[part 1 of 4: package /DBC_SysDesc/Pkg_Cluster]
AUTOSAR XML (schema 4-2-2)
package /DBC_SysDesc/Pkg_Cluster
  6 x j 1939 cluster, all with protocol-name=J1939:
    Can_Network_ACAN
      can physical channel Can_Network_ACAN_Channel: comm-connectors=Conn_Can_Network_ACAN_CGW
        frame EEC3DI_DCU_ACAN_IN: id 0x18FEDF3D, to CGW, frame-length=8, can-addressing-mode=EXTENDED, can-frame-rx-behavior=ANY
          pdu EEC3DI_DCU_ACAN_IN: length=8, transmission-mode-condition{data-filter={data-filter-type=ALWAYS, max=3, min=0, offset=0}, i-signal-in-i-pdu=NOx_Dew_Point_Start_Doosan_EEC3DI_DCU_ACAN}, transmission-mode-false-timing=event-controlled-timing=number-of-repetitions=0, transmission-mode-true-timing=event-controlled-timing=number-of-repetitions=0
            signal NOx_Dew_Point_Start_Doosan_EEC3DI_DCU_ACAN: start 58, 2 bit, little-endian, init-value=0, base-type=uint8, compu-method=CompuMethod_NOx_Dew_Point_Start_Doosan_EEC3DI_DCU, to CGW
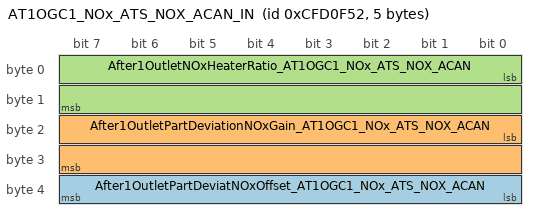
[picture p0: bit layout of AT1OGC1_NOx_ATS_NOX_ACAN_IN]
        frame AT1OGC1_NOx_ATS_NOX_ACAN_IN: id 0xCFD0F52, to CGW, frame-length=5, can-addressing-mode=EXTENDED, can-frame-rx-behavior=ANY
          pdu AT1OGC1_NOx_ATS_NOX_ACAN_IN: length=5, transmission-mode-false-timing=event-controlled-timing=number-of-repetitions=0, transmission-mode-true-timing=event-controlled-timing=number-of-repetitions=0
            transmission-mode-conditions:
              {data-filter={data-filter-type=ALWAYS, max=250, min=0}, i-signal-in-i-pdu=After1OutletPartDeviatNOxOffset_AT1OGC1_NOx_ATS_NOX_ACAN}
              {data-filter={data-filter-type=NEW-IS-WITHIN, max=2000, min=0}, i-signal-in-i-pdu=After1OutletPartDeviationNOxGain_AT1OGC1_NOx_ATS_NOX_ACAN}
              {data-filter={data-filter-type=NEW-IS-WITHIN, max=64255, min=0, offset=0}, i-signal-in-i-pdu=After1OutletNOxHeaterRatio_AT1OGC1_NOx_ATS_NOX_ACAN}
            signal After1OutletPartDeviatNOxOffset_AT1OGC1_NOx_ATS_NOX_ACAN: start 32, 8 bit, little-endian, init-value=0, base-type=uint8, compu {raw=phys+125 for phys -125..125; unit ppm}, to CGW  # New part deviation NOx_Offset to correct(recalculate) sensor signal on th Engine ECU sideNew part deviation NOx_Offset to correct(recalculate) sensor signal on th Engine ECU side"
            signal After1OutletPartDeviationNOxGain_AT1OGC1_NOx_ATS_NOX_ACAN: start 16, 16 bit, little-endian, init-value=0, base-type=uint16, compu {raw=phys*10+1000 for phys -100..100; unit pct}, to CGW  # New Part deviation NOx_Gain to correct(recalculate) sensor signal on the Engine ECU sideNew Part deviation NOx_Gain to correct(recalculate) sensor signal on the Engine ECU side"
            signal After1OutletNOxHeaterRatio_AT1OGC1_NOx_ATS_NOX_ACAN: start 0, 16 bit, little-endian, init-value=0, base-type=uint16, compu {raw=phys*1000 for phys 0..64.255}, to CGW  # Heater ratio to determine temperature at sensor tip.Heater ratio to determine temperature at sensor tip."
    Can_Network_CCAN
      can physical channel Can_Network_CCAN_Channel: comm-connectors=Conn_Can_Network_CCAN_CGW
        frame TPM_TPMS_CCAN_IN: id 0x18FFC833, to CGW, frame-length=8, can-addressing-mode=EXTENDED, can-frame-rx-behavior=ANY
          pdu TPM_TPMS_CCAN_IN: length=8, transmission-mode-false-timing=event-controlled-timing=number-of-repetitions=0, transmission-mode-true-timing=event-controlled-timing=number-of-repetitions=0
        frame DM1_TPMS_CCAN_IN: id 0x18FECA33, to CGW, frame-length=22, can-addressing-mode=EXTENDED, can-frame-rx-behavior=ANY
          pdu DM1_TPMS_CCAN_IN: length=22, transmission-mode-false-timing=event-controlled-timing=number-of-repetitions=0, transmission-mode-true-timing=event-controlled-timing=number-of-repetitions=0
        frame AC2TB_ACU_CCAN_IN: id 0x18FF4A53, to CGW, frame-length=8, can-addressing-mode=EXTENDED, can-frame-rx-behavior=ANY
          pdu AC2TB_ACU_CCAN_IN: length=8, transmission-mode-false-timing=event-controlled-timing=number-of-repetitions=0, transmission-mode-true-timing=event-controlled-timing=number-of-repetitions=0
        frame DM1_ACU_CCAN_IN: id 0x18FECA53, to CGW, frame-length=22, can-addressing-mode=EXTENDED, can-frame-rx-behavior=ANY
          pdu DM1_ACU_CCAN_IN: length=22, transmission-mode-false-timing=event-controlled-timing=number-of-repetitions=0, transmission-mode-true-timing=event-controlled-timing=number-of-repetitions=0
        frame TCO1_Tachograph_DTG_CAN_CLOCK_CCAN_IN: id 0xCFE6CEE, to CGW, frame-length=8, can-addressing-mode=EXTENDED, can-frame-rx-behavior=ANY
          pdu TCO1_Tachograph_DTG_CAN_CLOCK_CCAN_IN: length=8, transmission-mode-false-timing=event-controlled-timing=number-of-repetitions=0, transmission-mode-true-timing=event-controlled-timing=number-of-repetitions=0
        frame TD_DTG_CAN_CLOCK_CCAN_IN: id 0x18FEE6EE, to CGW, frame-length=8, can-addressing-mode=EXTENDED, can-frame-rx-behavior=ANY
          pdu TD_DTG_CAN_CLOCK_CCAN_IN: length=8, transmission-mode-false-timing=event-controlled-timing=number-of-repetitions=0, transmission-mode-true-timing=event-controlled-timing=number-of-repetitions=0
        frame TB2SM_T_BOX_T_LINK_CCAN_IN: id 0x18EF1F4A, to CGW, frame-length=8, can-addressing-mode=EXTENDED, can-frame-rx-behavior=ANY
          pdu TB2SM_T_BOX_T_LINK_CCAN_IN: length=8, transmission-mode-false-timing=event-controlled-timing=number-of-repetitions=0, transmission-mode-true-timing=event-controlled-timing=number-of-repetitions=0
        frame BDS_ACU_CCAN_IN: id 0x18FD1753, to CGW, frame-length=8, can-addressing-mode=EXTENDED, can-frame-rx-behavior=ANY
          pdu BDS_ACU_CCAN_IN: length=8, transmission-mode-false-timing=event-controlled-timing=number-of-repetitions=0, transmission-mode-true-timing=event-controlled-timing=number-of-repetitions=0
        frame AC2IC_ACU_CCAN_IN: id 0x18FF1753, to CGW, frame-length=8, can-addressing-mode=EXTENDED, can-frame-rx-behavior=ANY
          pdu AC2IC_ACU_CCAN_IN: length=8, transmission-mode-false-timing=event-controlled-timing=number-of-repetitions=0, transmission-mode-true-timing=event-controlled-timing=number-of-repetitions=0
        frame CACI5_HVAC_CCAN_IN: id 0x18FC1C19, to CGW, frame-length=8, can-addressing-mode=EXTENDED, can-frame-rx-behavior=ANY
          pdu CACI5_HVAC_CCAN_IN: length=8, transmission-mode-false-timing=event-controlled-timing=number-of-repetitions=0, transmission-mode-true-timing=event-controlled-timing=number-of-repetitions=0
        frame CACI6_HVAC_CCAN_IN: id 0x18FB1C19, to CGW, frame-length=8, can-addressing-mode=EXTENDED, can-frame-rx-behavior=ANY
          pdu CACI6_HVAC_CCAN_IN: length=8, transmission-mode-false-timing=event-controlled-timing=number-of-repetitions=0, transmission-mode-true-timing=event-controlled-timing=number-of-repetitions=0
        frame VDHR_Tachograph_DTG_CAN_CLOCK_CCAN_IN: id 0x18FEC1EE, to CGW, frame-length=8, can-addressing-mode=EXTENDED, can-frame-rx-behavior=ANY
          pdu VDHR_Tachograph_DTG_CAN_CLOCK_CCAN_IN: length=8, transmission-mode-false-timing=event-controlled-timing=number-of-repetitions=0, transmission-mode-true-timing=event-controlled-timing=number-of-repetitions=0
        frame ETC7_TCU_CCAN_OUT: id 0x18FE4A03, from CGW, frame-length=8, can-addressing-mode=EXTENDED
          pdu ETC7_TCU_CCAN_OUT: length=8, transmission-mode-false-timing=event-controlled-timing=number-of-repetitions=0, transmission-mode-true-timing=event-controlled-timing=number-of-repetitions=0
        frame TCO1_IC_CCAN_OUT: id 0xCFE6C17, from CGW, frame-length=8, can-addressing-mode=EXTENDED
          pdu TCO1_IC_CCAN_OUT: length=8, transmission-mode-false-timing=event-controlled-timing=number-of-repetitions=0, transmission-mode-true-timing=event-controlled-timing=number-of-repetitions=0
        frame EEC1_ECU_CCAN_OUT: id 0xCF00400, from CGW, frame-length=8, can-addressing-mode=EXTENDED
          pdu EEC1_ECU_CCAN_OUT: length=8, transmission-mode-false-timing=event-controlled-timing=number-of-repetitions=0, transmission-mode-true-timing=event-controlled-timing=number-of-repetitions=0
        frame SWRC2AVN_SWRC_CCAN_OUT: id 0x18FF1C66, from CGW, frame-length=8, can-addressing-mode=EXTENDED
          pdu SWRC2AVN_SWRC_CCAN_OUT: length=8, transmission-mode-false-timing=event-controlled-timing=number-of-repetitions=0, transmission-mode-true-timing=event-controlled-timing=number-of-repetitions=0
        frame TxCCVS_ECU_CCAN_OUT: id 0x18FEF100, from CGW, frame-length=8, can-addressing-mode=EXTENDED
          pdu TxCCVS_ECU_CCAN_OUT: length=8, transmission-mode-false-timing=event-controlled-timing=number-of-repetitions=0, transmission-mode-true-timing=event-controlled-timing=number-of-repetitions=0
        frame ETC2_TCU_CCAN_OUT: id 0x18F00503, from CGW, frame-length=8, can-addressing-mode=EXTENDED
          pdu ETC2_TCU_CCAN_OUT: length=8, transmission-mode-false-timing=event-controlled-timing=number-of-repetitions=0, transmission-mode-true-timing=event-controlled-timing=number-of-repetitions=0
        frame EBC2_ABS_EBS_CCAN_OUT: id 0x18FEBF0B, from CGW, frame-length=8, can-addressing-mode=EXTENDED
          pdu EBC2_ABS_EBS_CCAN_OUT: length=8, transmission-mode-false-timing=event-controlled-timing=number-of-repetitions=0, transmission-mode-true-timing=event-controlled-timing=number-of-repetitions=0
        frame VDHR_IC_CCAN_OUT: id 0x18FEC117, from CGW, frame-length=8, can-addressing-mode=EXTENDED
          pdu VDHR_IC_CCAN_OUT: length=8, transmission-mode-false-timing=event-controlled-timing=number-of-repetitions=0, transmission-mode-true-timing=event-controlled-timing=number-of-repetitions=0
        frame IC2BC_IC_CCAN_OUT: id 0x18FF2117, from CGW, frame-length=8, can-addressing-mode=EXTENDED
          pdu IC2BC_IC_CCAN_OUT: length=8, transmission-mode-false-timing=event-controlled-timing=number-of-repetitions=0, transmission-mode-true-timing=event-controlled-timing=number-of-repetitions=0
        frame SM2BC_SMK_CCAN_OUT: id 0x18FF211F, from CGW, frame-length=8, can-addressing-mode=EXTENDED
          pdu SM2BC_SMK_CCAN_OUT: length=8, transmission-mode-false-timing=event-controlled-timing=number-of-repetitions=0, transmission-mode-true-timing=event-controlled-timing=number-of-repetitions=0
        frame CCVS1_BCM_CMD_CCAN_OUT: id 0x18FEF121, from CGW, frame-length=8, can-addressing-mode=EXTENDED
          pdu CCVS1_BCM_CMD_CCAN_OUT: length=8, transmission-mode-false-timing=event-controlled-timing=number-of-repetitions=0, transmission-mode-true-timing=event-controlled-timing=number-of-repetitions=0
        frame OEL_IC_CCAN_OUT: id 0xCFDCC27, from CGW, frame-length=8, can-addressing-mode=EXTENDED
          pdu OEL_IC_CCAN_OUT: length=8, transmission-mode-false-timing=event-controlled-timing=number-of-repetitions=0, transmission-mode-true-timing=event-controlled-timing=number-of-repetitions=0
        frame BC2CC_BCM_CMD_CCAN_OUT: id 0x18FF4721, from CGW, frame-length=8, can-addressing-mode=EXTENDED
          pdu BC2CC_BCM_CMD_CCAN_OUT: length=8, transmission-mode-false-timing=event-controlled-timing=number-of-repetitions=0, transmission-mode-true-timing=event-controlled-timing=number-of-repetitions=0
    Can_Network_ECAN
      can physical channel Can_Network_ECAN_Channel: comm-connectors=Conn_Can_Network_ECAN_CGW
        frame DM1_EHPS_ECAN_IN: id 0x18FECA13, to CGW, frame-length=22, can-addressing-mode=EXTENDED, can-frame-rx-behavior=ANY
          pdu DM1_EHPS_ECAN_IN: length=22, transmission-mode-false-timing=event-controlled-timing=number-of-repetitions=0, transmission-mode-true-timing=event-controlled-timing=number-of-repetitions=0
        frame EPSO2_EHPS_ECAN_IN: id 0x18FF0613, to CGW, frame-length=8, can-addressing-mode=EXTENDED, can-frame-rx-behavior=ANY
          pdu EPSO2_EHPS_ECAN_IN: length=8, transmission-mode-false-timing=event-controlled-timing=number-of-repetitions=0, transmission-mode-true-timing=event-controlled-timing=number-of-repetitions=0
        frame CM3_AWD_ECAN_IN: id 0x18FDD465, to CGW, frame-length=8, can-addressing-mode=EXTENDED, can-frame-rx-behavior=ANY
          pdu CM3_AWD_ECAN_IN: length=8, transmission-mode-false-timing=event-controlled-timing=number-of-repetitions=0, transmission-mode-true-timing=event-controlled-timing=number-of-repetitions=0
        frame SAS1_EHPS_ECAN_IN: id 0x18F01D13, to CGW, frame-length=8, can-addressing-mode=EXTENDED, can-frame-rx-behavior=ANY
          pdu SAS1_EHPS_ECAN_IN: length=8, transmission-mode-false-timing=event-controlled-timing=number-of-repetitions=0, transmission-mode-true-timing=event-controlled-timing=number-of-repetitions=0
        frame SAS2_EHPS_ECAN_IN: id 0x18F01D14, to CGW, frame-length=8, can-addressing-mode=EXTENDED, can-frame-rx-behavior=ANY
          pdu SAS2_EHPS_ECAN_IN: length=8, transmission-mode-false-timing=event-controlled-timing=number-of-repetitions=0, transmission-mode-true-timing=event-controlled-timing=number-of-repetitions=0
        frame EPSO1_EHPS_ECAN_IN: id 0x18FF0513, to CGW, frame-length=8, can-addressing-mode=EXTENDED, can-frame-rx-behavior=ANY
          pdu EPSO1_EHPS_ECAN_IN: length=8, transmission-mode-false-timing=event-controlled-timing=number-of-repetitions=0, transmission-mode-true-timing=event-controlled-timing=number-of-repetitions=0
        frame ESS2IC_ESS_ECAN_IN: id 0x18FF174D, to CGW, frame-length=8, can-addressing-mode=EXTENDED, can-frame-rx-behavior=ANY
          pdu ESS2IC_ESS_ECAN_IN: length=8, transmission-mode-false-timing=event-controlled-timing=number-of-repetitions=0, transmission-mode-true-timing=event-controlled-timing=number-of-repetitions=0
        frame TCI_AWD_ECAN_IN: id 0x18FD8365, to CGW, frame-length=8, can-addressing-mode=EXTENDED, can-frame-rx-behavior=ANY
          pdu TCI_AWD_ECAN_IN: length=8, transmission-mode-false-timing=event-controlled-timing=number-of-repetitions=0, transmission-mode-true-timing=event-controlled-timing=number-of-repetitions=0
        frame EEC1_ECU_ECAN_OUT: id 0xCF00400, from CGW, frame-length=8, can-addressing-mode=EXTENDED
          pdu EEC1_ECU_ECAN_OUT: length=8, transmission-mode-false-timing=event-controlled-timing=number-of-repetitions=0, transmission-mode-true-timing=event-controlled-timing=number-of-repetitions=0
        frame TCO1_Tachograph_DTG_CAN_CLOCK_ECAN_OUT: id 0xCFE6CEE, from CGW, frame-length=8, can-addressing-mode=EXTENDED
          pdu TCO1_Tachograph_DTG_CAN_CLOCK_ECAN_OUT: length=8, transmission-mode-false-timing=event-controlled-timing=number-of-repetitions=0, transmission-mode-true-timing=event-controlled-timing=number-of-repetitions=0
        frame ETC2_TCU_ECAN_OUT: id 0x18F00503, from CGW, frame-length=8, can-addressing-mode=EXTENDED
          pdu ETC2_TCU_ECAN_OUT: length=8, transmission-mode-false-timing=event-controlled-timing=number-of-repetitions=0, transmission-mode-true-timing=event-controlled-timing=number-of-repetitions=0
    Can_Network_LCAN
      can physical channel Can_Network_LCAN_Channel: comm-connectors=Conn_Can_Network_LCAN_CGW
        frame EBC5_CCM_LCAN_IN: id 0x18FDC40B, to CGW, frame-length=4, can-addressing-mode=EXTENDED, can-frame-rx-behavior=ANY
          pdu EBC5_CCM_LCAN_IN: length=4, transmission-mode-false-timing=event-controlled-timing=number-of-repetitions=0, transmission-mode-true-timing=event-controlled-timing=number-of-repetitions=0
        frame SMK1__SM2TB__SMK_LCAN_IN: id 0x18EF4A1F, to CGW, frame-length=8, can-addressing-mode=EXTENDED, can-frame-rx-behavior=ANY
          pdu SMK1__SM2TB__SMK_LCAN_IN: length=8, transmission-mode-false-timing=event-controlled-timing=number-of-repetitions=0, transmission-mode-true-timing=event-controlled-timing=number-of-repetitions=0
        frame LWSV_CCM_LCAN_IN: id 0x18FF170B, to CGW, frame-length=8, can-addressing-mode=EXTENDED, can-frame-rx-behavior=ANY
          pdu LWSV_CCM_LCAN_IN: length=8, transmission-mode-false-timing=event-controlled-timing=number-of-repetitions=0, transmission-mode-true-timing=event-controlled-timing=number-of-repetitions=0
        frame EBC1_CCM_LCAN_IN: id 0x18F00131, to CGW, frame-length=8, can-addressing-mode=EXTENDED, can-frame-rx-behavior=ANY
          pdu EBC1_CCM_LCAN_IN: length=8, transmission-mode-false-timing=event-controlled-timing=number-of-repetitions=0, transmission-mode-true-timing=event-controlled-timing=number-of-repetitions=0
        frame CC2BC_CCM_LCAN_IN: id 0x18FF2147, to CGW, frame-length=2, can-addressing-mode=EXTENDED, can-frame-rx-behavior=ANY
          pdu CC2BC_CCM_LCAN_IN: length=2, transmission-mode-false-timing=event-controlled-timing=number-of-repetitions=0, transmission-mode-true-timing=event-controlled-timing=number-of-repetitions=0
        frame CC2IC_CCM_LCAN_IN: id 0x18FF1747, to CGW, frame-length=8, can-addressing-mode=EXTENDED, can-frame-rx-behavior=ANY
          pdu CC2IC_CCM_LCAN_IN: length=8, transmission-mode-false-timing=event-controlled-timing=number-of-repetitions=0, transmission-mode-true-timing=event-controlled-timing=number-of-repetitions=0
        frame EBC4_CCM_LCAN_IN: id 0x1CFEAC0B, to CGW, frame-length=8, can-addressing-mode=EXTENDED, can-frame-rx-behavior=ANY
          pdu EBC4_CCM_LCAN_IN: length=8, transmission-mode-false-timing=event-controlled-timing=number-of-repetitions=0, transmission-mode-true-timing=event-controlled-timing=number-of-repetitions=0
        frame EEC1_ECU_LCAN_OUT: id 0xCF00400, from CGW, frame-length=8, can-addressing-mode=EXTENDED
          pdu EEC1_ECU_LCAN_OUT: length=8, transmission-mode-false-timing=event-controlled-timing=number-of-repetitions=0, transmission-mode-true-timing=event-controlled-timing=number-of-repetitions=0
        frame AMB_ECU_LCAN_OUT: id 0x18FEF500, from CGW, frame-length=8, can-addressing-mode=EXTENDED
          pdu AMB_ECU_LCAN_OUT: length=8, transmission-mode-false-timing=event-controlled-timing=number-of-repetitions=0, transmission-mode-true-timing=event-controlled-timing=number-of-repetitions=0
    Can_Network_PCAN
      can physical channel Can_Network_PCAN_Channel: comm-connectors=Conn_Can_Network_PCAN_CGW
        frame ETC1_TCU_PCAN_IN: id 0xCF00203, to CGW, frame-length=8, can-addressing-mode=EXTENDED, can-frame-rx-behavior=ANY
          pdu ETC1_TCU_PCAN_IN: length=8, transmission-mode-false-timing=event-controlled-timing=number-of-repetitions=0, transmission-mode-true-timing=event-controlled-timing=number-of-repetitions=0
        frame ETC7_TCU_PCAN_IN: id 0x18FE4A03, to CGW, frame-length=8, can-addressing-mode=EXTENDED, can-frame-rx-behavior=ANY
          pdu ETC7_TCU_PCAN_IN: length=8, transmission-mode-false-timing=event-controlled-timing=number-of-repetitions=0, transmission-mode-true-timing=event-controlled-timing=number-of-repetitions=0
        frame ERC1_ER_ECU_PCAN_IN: id 0x18F0000F, to CGW, frame-length=8, can-addressing-mode=EXTENDED, can-frame-rx-behavior=ANY
          pdu ERC1_ER_ECU_PCAN_IN: length=8, transmission-mode-false-timing=event-controlled-timing=number-of-repetitions=0, transmission-mode-true-timing=event-controlled-timing=number-of-repetitions=0
        frame ERC1_DR_ITR_PCAN_IN: id 0x18F00010, to CGW, frame-length=8, can-addressing-mode=EXTENDED, can-frame-rx-behavior=ANY
          pdu ERC1_DR_ITR_PCAN_IN: length=8, transmission-mode-false-timing=event-controlled-timing=number-of-repetitions=0, transmission-mode-true-timing=event-controlled-timing=number-of-repetitions=0
        frame RQST_I_IC_PCAN_IN: id 0x18EA0017, to CGW, frame-length=8, can-addressing-mode=EXTENDED, can-frame-rx-behavior=ANY
          pdu RQST_I_IC_PCAN_IN: length=8, transmission-mode-false-timing=event-controlled-timing=number-of-repetitions=0, transmission-mode-true-timing=event-controlled-timing=number-of-repetitions=0
        frame TCO1_IC_PCAN_IN: id 0xCFE6C17, to CGW, frame-length=8, can-addressing-mode=EXTENDED, can-frame-rx-behavior=ANY
          pdu TCO1_IC_PCAN_IN: length=8, transmission-mode-false-timing=event-controlled-timing=number-of-repetitions=0, transmission-mode-true-timing=event-controlled-timing=number-of-repetitions=0
        frame ETC7_BCM_CMD_PCAN_IN: id 0x18FE4A21, to CGW, frame-length=8, can-addressing-mode=EXTENDED, can-frame-rx-behavior=ANY
          pdu ETC7_BCM_CMD_PCAN_IN: length=8, transmission-mode-false-timing=event-controlled-timing=number-of-repetitions=0, transmission-mode-true-timing=event-controlled-timing=number-of-repetitions=0
        frame EEC1_ECU_PCAN_IN: id 0xCF00400, to CGW, frame-length=8, can-addressing-mode=EXTENDED, can-frame-rx-behavior=ANY
          pdu EEC1_ECU_PCAN_IN: length=8, transmission-mode-false-timing=event-controlled-timing=number-of-repetitions=0, transmission-mode-true-timing=event-controlled-timing=number-of-repetitions=0
        frame RQST_D_IC_PCAN_IN: id 0x18EA0027, to CGW, frame-length=8, can-addressing-mode=EXTENDED, can-frame-rx-behavior=ANY
          pdu RQST_D_IC_PCAN_IN: length=8, transmission-mode-false-timing=event-controlled-timing=number-of-repetitions=0, transmission-mode-true-timing=event-controlled-timing=number-of-repetitions=0
        frame Brakes_RTM_PCAN_IN: id 0x18FEFA27, to CGW, frame-length=8, can-addressing-mode=EXTENDED, can-frame-rx-behavior=ANY
          pdu Brakes_RTM_PCAN_IN: length=8, transmission-mode-false-timing=event-controlled-timing=number-of-repetitions=0, transmission-mode-true-timing=event-controlled-timing=number-of-repetitions=0
        frame AIR1_IC_PCAN_IN: id 0x18FEAE30, to CGW, frame-length=8, can-addressing-mode=EXTENDED, can-frame-rx-behavior=ANY
          pdu AIR1_IC_PCAN_IN: length=8, transmission-mode-false-timing=event-controlled-timing=number-of-repetitions=0, transmission-mode-true-timing=event-controlled-timing=number-of-repetitions=0
        frame AMB_ECU_PCAN_IN: id 0x18FEF500, to CGW, frame-length=8, can-addressing-mode=EXTENDED, can-frame-rx-behavior=ANY
          pdu AMB_ECU_PCAN_IN: length=8, transmission-mode-false-timing=event-controlled-timing=number-of-repetitions=0, transmission-mode-true-timing=event-controlled-timing=number-of-repetitions=0
        frame CCVS3_ECU_PCAN_IN: id 0x18FCDC00, to CGW, frame-length=1, can-addressing-mode=EXTENDED, can-frame-rx-behavior=ANY
          pdu CCVS3_ECU_PCAN_IN: length=1, transmission-mode-false-timing=event-controlled-timing=number-of-repetitions=0, transmission-mode-true-timing=event-controlled-timing=number-of-repetitions=0
        frame TxCCVS_ECU_PCAN_IN: id 0x18FEF100, to CGW, frame-length=8, can-addressing-mode=EXTENDED, can-frame-rx-behavior=ANY
          pdu TxCCVS_ECU_PCAN_IN: length=8, transmission-mode-false-timing=event-controlled-timing=number-of-repetitions=0, transmission-mode-true-timing=event-controlled-timing=number-of-repetitions=0
        frame EEC3_ECU_PCAN_IN: id 0x18FEDF00, to CGW, frame-length=8, can-addressing-mode=EXTENDED, can-frame-rx-behavior=ANY
          pdu EEC3_ECU_PCAN_IN: length=8, transmission-mode-false-timing=event-controlled-timing=number-of-repetitions=0, transmission-mode-true-timing=event-controlled-timing=number-of-repetitions=0
        frame EC1_ECU_PCAN_IN: id 0x18FEE300, to CGW, frame-length=39, can-addressing-mode=EXTENDED, can-frame-rx-behavior=ANY
          pdu EC1_ECU_PCAN_IN: length=39, transmission-mode-false-timing=event-controlled-timing=number-of-repetitions=0, transmission-mode-true-timing=event-controlled-timing=number-of-repetitions=0
        frame EEC2_ECU_PCAN_IN: id 0xCF00300, to CGW, frame-length=8, can-addressing-mode=EXTENDED, can-frame-rx-behavior=ANY
          pdu EEC2_ECU_PCAN_IN: length=8, transmission-mode-false-timing=event-controlled-timing=number-of-repetitions=0, transmission-mode-true-timing=event-controlled-timing=number-of-repetitions=0
        frame ETC2_TCU_PCAN_IN: id 0x18F00503, to CGW, frame-length=8, can-addressing-mode=EXTENDED, can-frame-rx-behavior=ANY
          pdu ETC2_TCU_PCAN_IN: length=8, transmission-mode-false-timing=event-controlled-timing=number-of-repetitions=0, transmission-mode-true-timing=event-controlled-timing=number-of-repetitions=0
        frame VDHR_IC_PCAN_IN: id 0x18FEC117, to CGW, frame-length=8, can-addressing-mode=EXTENDED, can-frame-rx-behavior=ANY
          pdu VDHR_IC_PCAN_IN: length=8, transmission-mode-false-timing=event-controlled-timing=number-of-repetitions=0, transmission-mode-true-timing=event-controlled-timing=number-of-repetitions=0
        frame IC2BC_IC_PCAN_IN: id 0x18FF2117, to CGW, frame-length=8, can-addressing-mode=EXTENDED, can-frame-rx-behavior=ANY
          pdu IC2BC_IC_PCAN_IN: length=8, transmission-mode-false-timing=event-controlled-timing=number-of-repetitions=0, transmission-mode-true-timing=event-controlled-timing=number-of-repetitions=0
        frame IC2SP1_IC_PCAN_IN: id 0x18FF3117, to CGW, frame-length=8, can-addressing-mode=EXTENDED, can-frame-rx-behavior=ANY
          pdu IC2SP1_IC_PCAN_IN: length=8, transmission-mode-false-timing=event-controlled-timing=number-of-repetitions=0, transmission-mode-true-timing=event-controlled-timing=number-of-repetitions=0
        frame IC2SP2_IC_PCAN_IN: id 0x18FB3117, to CGW, frame-length=8, can-addressing-mode=EXTENDED, can-frame-rx-behavior=ANY
          pdu IC2SP2_IC_PCAN_IN: length=8, transmission-mode-false-timing=event-controlled-timing=number-of-repetitions=0, transmission-mode-true-timing=event-controlled-timing=number-of-repetitions=0
        frame RQST_EBC4_IC_PCAN_IN: id 0x18EA0B17, to CGW, frame-length=8, can-addressing-mode=EXTENDED, can-frame-rx-behavior=ANY
          pdu RQST_EBC4_IC_PCAN_IN: length=8, transmission-mode-false-timing=event-controlled-timing=number-of-repetitions=0, transmission-mode-true-timing=event-controlled-timing=number-of-repetitions=0
        frame SM2BC_SMK_PCAN_IN: id 0x18FF211F, to CGW, frame-length=8, can-addressing-mode=EXTENDED, can-frame-rx-behavior=ANY
          pdu SM2BC_SMK_PCAN_IN: length=8, transmission-mode-false-timing=event-controlled-timing=number-of-repetitions=0, transmission-mode-true-timing=event-controlled-timing=number-of-repetitions=0
        frame CCVS1_BCM_CMD_PCAN_IN: id 0x18FEF121, to CGW, frame-length=8, can-addressing-mode=EXTENDED, can-frame-rx-behavior=ANY
          pdu CCVS1_BCM_CMD_PCAN_IN: length=8, transmission-mode-false-timing=event-controlled-timing=number-of-repetitions=0, transmission-mode-true-timing=event-controlled-timing=number-of-repetitions=0
        frame OEL_IC_PCAN_IN: id 0xCFDCC27, to CGW, frame-length=8, can-addressing-mode=EXTENDED, can-frame-rx-behavior=ANY
          pdu OEL_IC_PCAN_IN: length=8, transmission-mode-false-timing=event-controlled-timing=number-of-repetitions=0, transmission-mode-true-timing=event-controlled-timing=number-of-repetitions=0
        frame CCVS1_SA2_RTM_PCAN_IN: id 0x18FEF127, to CGW, frame-length=8, can-addressing-mode=EXTENDED, can-frame-rx-behavior=ANY
          pdu CCVS1_SA2_RTM_PCAN_IN: length=8, transmission-mode-false-timing=event-controlled-timing=number-of-repetitions=0, transmission-mode-true-timing=event-controlled-timing=number-of-repetitions=0
        frame ASC2_A_BCM_CMD_PCAN_IN: id 0xCD22F27, to CGW, frame-length=8, can-addressing-mode=EXTENDED, can-frame-rx-behavior=ANY
          pdu ASC2_A_BCM_CMD_PCAN_IN: length=8, transmission-mode-false-timing=event-controlled-timing=number-of-repetitions=0, transmission-mode-true-timing=event-controlled-timing=number-of-repetitions=0
        frame BC2CC_BCM_CMD_PCAN_IN: id 0x18FF4721, to CGW, frame-length=8, can-addressing-mode=EXTENDED, can-frame-rx-behavior=ANY
          pdu BC2CC_BCM_CMD_PCAN_IN: length=8, transmission-mode-false-timing=event-controlled-timing=number-of-repetitions=0, transmission-mode-true-timing=event-controlled-timing=number-of-repetitions=0
        frame TSC1_E_ABS_EBS_PCAN_OUT: id 0xC00000B, from CGW, frame-length=8, can-addressing-mode=EXTENDED
          pdu TSC1_E_ABS_EBS_PCAN_OUT: length=8, transmission-mode-false-timing=event-controlled-timing=number-of-repetitions=0, transmission-mode-true-timing=event-controlled-timing=number-of-repetitions=0
        frame TSC1_DR_ABS_EBS_PCAN_OUT: id 0xC00100B, from CGW, frame-length=8, can-addressing-mode=EXTENDED
          pdu TSC1_DR_ABS_EBS_PCAN_OUT: length=8, transmission-mode-false-timing=event-controlled-timing=number-of-repetitions=0, transmission-mode-true-timing=event-controlled-timing=number-of-repetitions=0
        frame DM1_ABS_EBS_PCAN_OUT: id 0x18FECA0B, from CGW, frame-length=22, can-addressing-mode=EXTENDED
          pdu DM1_ABS_EBS_PCAN_OUT: length=22, transmission-mode-false-timing=event-controlled-timing=number-of-repetitions=0, transmission-mode-true-timing=event-controlled-timing=number-of-repetitions=0
        frame DM1_EHPS_PCAN_OUT: id 0x18FECA13, from CGW, frame-length=22, can-addressing-mode=EXTENDED
          pdu DM1_EHPS_PCAN_OUT: length=22, transmission-mode-false-timing=event-controlled-timing=number-of-repetitions=0, transmission-mode-true-timing=event-controlled-timing=number-of-repetitions=0
        frame EBC5_ABS_EBS_PCAN_OUT: id 0x18FDC40B, from CGW, frame-length=4, can-addressing-mode=EXTENDED
          pdu EBC5_ABS_EBS_PCAN_OUT: length=4, transmission-mode-false-timing=event-controlled-timing=number-of-repetitions=0, transmission-mode-true-timing=event-controlled-timing=number-of-repetitions=0
            transmission-mode-conditions:
              {data-filter={data-filter-type=ALWAYS, max=250, min=0}, i-signal-in-i-pdu=OverallIntendedBrakeAcceleration_EBC5_ABS_EBS_PCAN}
              {data-filter={data-filter-type=ALWAYS, max=250, min=0}, i-signal-in-i-pdu=DriverBrakeDemand_EBC5_ABS_EBS_PCAN}
              {data-filter={data-filter-type=ALWAYS, max=15, min=0, offset=0}, i-signal-in-i-pdu=XBRBrakeHoldMode_EBC5_ABS_EBS_PCAN}
              {data-filter={data-filter-type=ALWAYS, max=3, min=0, offset=0}, i-signal-in-i-pdu=RailroadMode_EBC5_ABS_EBS_PCAN}
              {data-filter={data-filter-type=ALWAYS, max=0, min=0, offset=0}, i-signal-in-i-pdu=EmergencyBrakingActive_EBC5_ABS_EBS_PCAN}
              {data-filter={data-filter-type=ALWAYS, max=3, min=0, offset=0}, i-signal-in-i-pdu=BrakeTempWarning_EBC5_ABS_EBS_PCAN}
              {data-filter={data-filter-type=ALWAYS, max=250, min=0}, i-signal-in-i-pdu=XBRAccelerationLimit_EBC5_ABS_EBS_PCAN}
              {data-filter={data-filter-type=ALWAYS, max=15, min=0, offset=0}, i-signal-in-i-pdu=XBRActiveCtrlMode_EBC5_ABS_EBS_PCAN}
              {data-filter={data-filter-type=ALWAYS, max=3, min=0, offset=0}, i-signal-in-i-pdu=XBRSystemState_EBC5_ABS_EBS_PCAN}
              {data-filter={data-filter-type=ALWAYS, max=3, min=0, offset=0}, i-signal-in-i-pdu=FoundationBrakeUse_EBC5_ABS_EBS_PCAN}
              {data-filter={data-filter-type=ALWAYS, max=7, min=0, offset=0}, i-signal-in-i-pdu=HillHolderMode_EBC5_ABS_EBS_PCAN}
              {data-filter={data-filter-type=ALWAYS, max=7, min=0, offset=0}, i-signal-in-i-pdu=HaltBrakeMode_EBC5_ABS_EBS_PCAN}
              {data-filter={data-filter-type=ALWAYS, max=3, min=0, offset=0}, i-signal-in-i-pdu=PrkngBrakeActuatorFullyActivated_EBC5_ABS_EBS_PCAN}
            signal OverallIntendedBrakeAcceleration_EBC5_ABS_EBS_PCAN: start 48, 8 bit, little-endian, init-value=0, base-type=uint8
            signal DriverBrakeDemand_EBC5_ABS_EBS_PCAN: start 40, 8 bit, little-endian, init-value=0, base-type=uint8
            signal XBRBrakeHoldMode_EBC5_ABS_EBS_PCAN: start 32, 4 bit, little-endian, init-value=0, base-type=uint8
            signal RailroadMode_EBC5_ABS_EBS_PCAN: start 28, 2 bit, little-endian, init-value=0, base-type=uint8
            signal EmergencyBrakingActive_EBC5_ABS_EBS_PCAN: start 26, 2 bit, little-endian, init-value=0, base-type=uint8
            signal BrakeTempWarning_EBC5_ABS_EBS_PCAN: start 0, 2 bit, little-endian, init-value=0, base-type=uint8
            signal XBRAccelerationLimit_EBC5_ABS_EBS_PCAN: start 16, 8 bit, little-endian, init-value=0, base-type=uint8
            signal XBRActiveCtrlMode_EBC5_ABS_EBS_PCAN: start 12, 4 bit, little-endian, init-value=0, base-type=uint8
            signal XBRSystemState_EBC5_ABS_EBS_PCAN: start 10, 2 bit, little-endian, init-value=0, base-type=uint8
            signal FoundationBrakeUse_EBC5_ABS_EBS_PCAN: start 8, 2 bit, little-endian, init-value=0, base-type=uint8
            signal HillHolderMode_EBC5_ABS_EBS_PCAN: start 5, 3 bit, little-endian, init-value=0, base-type=uint8
            signal HaltBrakeMode_EBC5_ABS_EBS_PCAN: start 2, 3 bit, little-endian, init-value=0, base-type=uint8
            signal PrkngBrakeActuatorFullyActivated_EBC5_ABS_EBS_PCAN: start 24, 2 bit, little-endian, init-value=0, base-type=uint8
        frame EBC5_CCM_PCAN_OUT: id 0x18FDC40B, from CGW, frame-length=4, can-addressing-mode=EXTENDED
          pdu EBC5_CCM_PCAN_OUT: length=4, transmission-mode-false-timing=event-controlled-timing=number-of-repetitions=0, transmission-mode-true-timing=event-controlled-timing=number-of-repetitions=0
        frame SMK1__SM2TB__SMK_PCAN_OUT: id 0x18EF4A1F, from CGW, frame-length=8, can-addressing-mode=EXTENDED
          pdu SMK1__SM2TB__SMK_PCAN_OUT: length=8, transmission-mode-false-timing=event-controlled-timing=number-of-repetitions=0, transmission-mode-true-timing=event-controlled-timing=number-of-repetitions=0
        frame TSC1_DrvR_ACC_ACC_PCAN_OUT: id 0xC00102A, from CGW, frame-length=8, can-addressing-mode=EXTENDED
          pdu TSC1_DrvR_ACC_ACC_PCAN_OUT: length=8, transmission-mode-false-timing=event-controlled-timing=number-of-repetitions=0, transmission-mode-true-timing=event-controlled-timing=number-of-repetitions=0
        frame DM1_ACC_ACC_PCAN_OUT: id 0x18FECA2A, from CGW, frame-length=22, can-addressing-mode=EXTENDED
          pdu DM1_ACC_ACC_PCAN_OUT: length=22, transmission-mode-false-timing=event-controlled-timing=number-of-repetitions=0, transmission-mode-true-timing=event-controlled-timing=number-of-repetitions=0
        frame DM1_ECAS_PCAN_OUT: id 0x18FECA2F, from CGW, frame-length=22, can-addressing-mode=EXTENDED
          pdu DM1_ECAS_PCAN_OUT: length=22, transmission-mode-false-timing=event-controlled-timing=number-of-repetitions=0, transmission-mode-true-timing=event-controlled-timing=number-of-repetitions=0
        frame FLIC_LDW_FCW_SWRC_PCAN_OUT: id 0x18A90031, from CGW, frame-length=8, can-addressing-mode=EXTENDED
          pdu FLIC_LDW_FCW_SWRC_PCAN_OUT: length=8, transmission-mode-condition{data-filter={data-filter-type=ALWAYS, max=3, min=0, offset=0}, i-signal-in-i-pdu=LaneDepartureWarningEnableCmd_FLIC_LDW_FCW_SWRC_PCAN}, transmission-mode-false-timing=event-controlled-timing=number-of-repetitions=0, transmission-mode-true-timing=event-controlled-timing=number-of-repetitions=0
            signal LaneDepartureWarningEnableCmd_FLIC_LDW_FCW_SWRC_PCAN: start 0, 2 bit, little-endian, init-value=0, base-type=uint8
        frame TPM_TPMS_PCAN_OUT: id 0x18FFC833, from CGW, frame-length=8, can-addressing-mode=EXTENDED
          pdu TPM_TPMS_PCAN_OUT: length=8, transmission-mode-false-timing=event-controlled-timing=number-of-repetitions=0, transmission-mode-true-timing=event-controlled-timing=number-of-repetitions=0
        frame VW_ALCS_ECAS_PCAN_OUT: id 0x18FEEA2F, from CGW, frame-length=8, can-addressing-mode=EXTENDED
          pdu VW_ALCS_ECAS_PCAN_OUT: length=8, transmission-mode-false-timing=event-controlled-timing=number-of-repetitions=0, transmission-mode-true-timing=event-controlled-timing=number-of-repetitions=0
        frame ASC1_A_ECAS_ECAS_PCAN_OUT: id 0xCFE5A2F, from CGW, frame-length=8, can-addressing-mode=EXTENDED
          pdu ASC1_A_ECAS_ECAS_PCAN_OUT: length=8, transmission-mode-false-timing=event-controlled-timing=number-of-repetitions=0, transmission-mode-true-timing=event-controlled-timing=number-of-repetitions=0
        frame DM1_TPMS_PCAN_OUT: id 0x18FECA33, from CGW, frame-length=22, can-addressing-mode=EXTENDED
          pdu DM1_TPMS_PCAN_OUT: length=22, transmission-mode-false-timing=event-controlled-timing=number-of-repetitions=0, transmission-mode-true-timing=event-controlled-timing=number-of-repetitions=0
        frame DM1_DSM_PCAN_OUT: id 0x18FECA41, from CGW, frame-length=22, can-addressing-mode=EXTENDED
          pdu DM1_DSM_PCAN_OUT: length=22, transmission-mode-false-timing=event-controlled-timing=number-of-repetitions=0, transmission-mode-true-timing=event-controlled-timing=number-of-repetitions=0
        frame AC2TB_ACU_PCAN_OUT: id 0x18FF4A53, from CGW, frame-length=8, can-addressing-mode=EXTENDED
          pdu AC2TB_ACU_PCAN_OUT: length=8, transmission-mode-false-timing=event-controlled-timing=number-of-repetitions=0, transmission-mode-true-timing=event-controlled-timing=number-of-repetitions=0
        frame DM1_ACU_PCAN_OUT: id 0x18FECA53, from CGW, frame-length=22, can-addressing-mode=EXTENDED
          pdu DM1_ACU_PCAN_OUT: length=22, transmission-mode-false-timing=event-controlled-timing=number-of-repetitions=0, transmission-mode-true-timing=event-controlled-timing=number-of-repetitions=0
        frame CM3_AWD_PCAN_OUT: id 0x18FDD465, from CGW, frame-length=8, can-addressing-mode=EXTENDED
          pdu CM3_AWD_PCAN_OUT: length=8, transmission-mode-false-timing=event-controlled-timing=number-of-repetitions=0, transmission-mode-true-timing=event-controlled-timing=number-of-repetitions=0
        frame DM1_PAS_PCAN_OUT: id 0x18FECA7A, from CGW, frame-length=22, can-addressing-mode=EXTENDED
          pdu DM1_PAS_PCAN_OUT: length=22, transmission-mode-false-timing=event-controlled-timing=number-of-repetitions=0, transmission-mode-true-timing=event-controlled-timing=number-of-repetitions=0
        frame DM01_AEBS_AEB_PCAN_OUT: id 0x18FECAA0, from CGW, frame-length=22, can-addressing-mode=EXTENDED
          pdu DM01_AEBS_AEB_PCAN_OUT: length=22, transmission-mode-false-timing=event-controlled-timing=number-of-repetitions=0, transmission-mode-true-timing=event-controlled-timing=number-of-repetitions=0
        frame DM1_LDW_FCW_PCAN_OUT: id 0x18FECAE8, from CGW, frame-length=22, can-addressing-mode=EXTENDED
          pdu DM1_LDW_FCW_PCAN_OUT: length=22, transmission-mode-false-timing=event-controlled-timing=number-of-repetitions=0, transmission-mode-true-timing=event-controlled-timing=number-of-repetitions=0
        frame TCO1_Tachograph_DTG_CAN_CLOCK_PCAN_OUT: id 0xCFE6CEE, from CGW, frame-length=8, can-addressing-mode=EXTENDED
          pdu TCO1_Tachograph_DTG_CAN_CLOCK_PCAN_OUT: length=8, transmission-mode-false-timing=event-controlled-timing=number-of-repetitions=0, transmission-mode-true-timing=event-controlled-timing=number-of-repetitions=0
        frame TD_DTG_CAN_CLOCK_PCAN_OUT: id 0x18FEE6EE, from CGW, frame-length=8, can-addressing-mode=EXTENDED
          pdu TD_DTG_CAN_CLOCK_PCAN_OUT: length=8, transmission-mode-false-timing=event-controlled-timing=number-of-repetitions=0, transmission-mode-true-timing=event-controlled-timing=number-of-repetitions=0
        frame TSC1_EXR_ABS_EBS_PCAN_OUT: id 0xC00290B, from CGW, frame-length=8, can-addressing-mode=EXTENDED
          pdu TSC1_EXR_ABS_EBS_PCAN_OUT: length=8, transmission-mode-false-timing=event-controlled-timing=number-of-repetitions=0, transmission-mode-true-timing=event-controlled-timing=number-of-repetitions=0
        frame EBC1_ABS_EBS_PCAN_OUT: id 0x18F0010B, from CGW, frame-length=8, can-addressing-mode=EXTENDED
          pdu EBC1_ABS_EBS_PCAN_OUT: length=8, transmission-mode-false-timing=event-controlled-timing=number-of-repetitions=0, transmission-mode-true-timing=event-controlled-timing=number-of-repetitions=0
        frame LWSV_CCM_PCAN_OUT: id 0x18FF170B, from CGW, frame-length=8, can-addressing-mode=EXTENDED
          pdu LWSV_CCM_PCAN_OUT: length=8, transmission-mode-false-timing=event-controlled-timing=number-of-repetitions=0, transmission-mode-true-timing=event-controlled-timing=number-of-repetitions=0
        frame EBC2_ABS_EBS_PCAN_OUT: id 0x18FEBF0B, from CGW, frame-length=8, can-addressing-mode=EXTENDED
          pdu EBC2_ABS_EBS_PCAN_OUT: length=8, transmission-mode-false-timing=event-controlled-timing=number-of-repetitions=0, transmission-mode-true-timing=event-controlled-timing=number-of-repetitions=0
        frame TSC1_ER_ABS_EBS_PCAN_OUT: id 0xC000F0B, from CGW, frame-length=8, can-addressing-mode=EXTENDED
          pdu TSC1_ER_ABS_EBS_PCAN_OUT: length=8, transmission-mode-false-timing=event-controlled-timing=number-of-repetitions=0, transmission-mode-true-timing=event-controlled-timing=number-of-repetitions=0
        frame VDC1_ABS_EBS_PCAN_OUT: id 0x18FE4F0B, from CGW, frame-length=8, can-addressing-mode=EXTENDED
          pdu VDC1_ABS_EBS_PCAN_OUT: length=8, transmission-mode-false-timing=event-controlled-timing=number-of-repetitions=0, transmission-mode-true-timing=event-controlled-timing=number-of-repetitions=0
        frame EPSO1_EHPS_PCAN_OUT: id 0x18FF0513, from CGW, frame-length=8, can-addressing-mode=EXTENDED
          pdu EPSO1_EHPS_PCAN_OUT: length=8, transmission-mode-false-timing=event-controlled-timing=number-of-repetitions=0, transmission-mode-true-timing=event-controlled-timing=number-of-repetitions=0
        frame ACC1_ACC_ACC_PCAN_OUT: id 0x10FE6F2A, from CGW, frame-length=8, can-addressing-mode=EXTENDED
          pdu ACC1_ACC_ACC_PCAN_OUT: length=8, transmission-mode-false-timing=event-controlled-timing=number-of-repetitions=0, transmission-mode-true-timing=event-controlled-timing=number-of-repetitions=0
        frame EBC1_CCM_PCAN_OUT: id 0x18F00131, from CGW, frame-length=8, can-addressing-mode=EXTENDED
          pdu EBC1_CCM_PCAN_OUT: length=8, transmission-mode-false-timing=event-controlled-timing=number-of-repetitions=0, transmission-mode-true-timing=event-controlled-timing=number-of-repetitions=0
        frame ACC2_SMD_SMD_PCAN_OUT: id 0x18FE5131, from CGW, frame-length=8, can-addressing-mode=EXTENDED
          pdu ACC2_SMD_SMD_PCAN_OUT: length=8, transmission-mode-false-timing=event-controlled-timing=number-of-repetitions=0, transmission-mode-true-timing=event-controlled-timing=number-of-repetitions=0
        frame ACC2_SWRC_SWRC_PCAN_OUT: id 0x18FE5131, from CGW, frame-length=8, can-addressing-mode=EXTENDED
          pdu ACC2_SWRC_SWRC_PCAN_OUT: length=8, transmission-mode-false-timing=event-controlled-timing=number-of-repetitions=0, transmission-mode-true-timing=event-controlled-timing=number-of-repetitions=0
        frame DSM1_DSM_PCAN_OUT: id 0x18FF1741, from CGW, frame-length=8, can-addressing-mode=EXTENDED
          pdu DSM1_DSM_PCAN_OUT: length=8, transmission-mode-false-timing=event-controlled-timing=number-of-repetitions=0, transmission-mode-true-timing=event-controlled-timing=number-of-repetitions=0
        frame CC2BC_CCM_PCAN_OUT: id 0x18FF2147, from CGW, frame-length=2, can-addressing-mode=EXTENDED
          pdu CC2BC_CCM_PCAN_OUT: length=2, transmission-mode-false-timing=event-controlled-timing=number-of-repetitions=0, transmission-mode-true-timing=event-controlled-timing=number-of-repetitions=0
        frame CC2IC_CCM_PCAN_OUT: id 0x18FF1747, from CGW, frame-length=8, can-addressing-mode=EXTENDED
          pdu CC2IC_CCM_PCAN_OUT: length=8, transmission-mode-false-timing=event-controlled-timing=number-of-repetitions=0, transmission-mode-true-timing=event-controlled-timing=number-of-repetitions=0
        frame TB2SM_T_BOX_T_LINK_PCAN_OUT: id 0x18EF1F4A, from CGW, frame-length=8, can-addressing-mode=EXTENDED
          pdu TB2SM_T_BOX_T_LINK_PCAN_OUT: length=8, transmission-mode-false-timing=event-controlled-timing=number-of-repetitions=0, transmission-mode-true-timing=event-controlled-timing=number-of-repetitions=0
        frame ESS2IC_ESS_PCAN_OUT: id 0x18FF174D, from CGW, frame-length=8, can-addressing-mode=EXTENDED
          pdu ESS2IC_ESS_PCAN_OUT: length=8, transmission-mode-false-timing=event-controlled-timing=number-of-repetitions=0, transmission-mode-true-timing=event-controlled-timing=number-of-repetitions=0
        frame BDS_ACU_PCAN_OUT: id 0x18FD1753, from CGW, frame-length=8, can-addressing-mode=EXTENDED
          pdu BDS_ACU_PCAN_OUT: length=8, transmission-mode-false-timing=event-controlled-timing=number-of-repetitions=0, transmission-mode-true-timing=event-controlled-timing=number-of-repetitions=0
        frame AC2IC_ACU_PCAN_OUT: id 0x18FF1753, from CGW, frame-length=8, can-addressing-mode=EXTENDED
          pdu AC2IC_ACU_PCAN_OUT: length=8, transmission-mode-false-timing=event-controlled-timing=number-of-repetitions=0, transmission-mode-true-timing=event-controlled-timing=number-of-repetitions=0
        frame TCI_AWD_PCAN_OUT: id 0x18FD8365, from CGW, frame-length=8, can-addressing-mode=EXTENDED
          pdu TCI_AWD_PCAN_OUT: length=8, transmission-mode-false-timing=event-controlled-timing=number-of-repetitions=0, transmission-mode-true-timing=event-controlled-timing=number-of-repetitions=0
        frame SWRC2IC_SWRC_PCAN_OUT: id 0x18FB1766, from CGW, frame-length=8, can-addressing-mode=EXTENDED
          pdu SWRC2IC_SWRC_PCAN_OUT: length=8, transmission-mode-false-timing=event-controlled-timing=number-of-repetitions=0, transmission-mode-true-timing=event-controlled-timing=number-of-repetitions=0
        frame CWI1_PAS_PCAN_OUT: id 0x18E0177A, from CGW, frame-length=8, can-addressing-mode=EXTENDED
          pdu CWI1_PAS_PCAN_OUT: length=8, transmission-mode-false-timing=event-controlled-timing=number-of-repetitions=0, transmission-mode-true-timing=event-controlled-timing=number-of-repetitions=0
        frame CWI2_PAS_PCAN_OUT: id 0x18E1177A, from CGW, frame-length=8, can-addressing-mode=EXTENDED
          pdu CWI2_PAS_PCAN_OUT: length=8, transmission-mode-false-timing=event-controlled-timing=number-of-repetitions=0, transmission-mode-true-timing=event-controlled-timing=number-of-repetitions=0
        frame EBC4_CCM_PCAN_OUT: id 0x1CFEAC0B, from CGW, frame-length=8, can-addressing-mode=EXTENDED
          pdu EBC4_CCM_PCAN_OUT: length=8, transmission-mode-false-timing=event-controlled-timing=number-of-repetitions=0, transmission-mode-true-timing=event-controlled-timing=number-of-repetitions=0
        frame AEBS1_AEBS_AEB_PCAN_OUT: id 0xCF02FA0, from CGW, frame-length=8, can-addressing-mode=EXTENDED
          pdu AEBS1_AEBS_AEB_PCAN_OUT: length=8, transmission-mode-false-timing=event-controlled-timing=number-of-repetitions=0, transmission-mode-true-timing=event-controlled-timing=number-of-repetitions=0
        frame FLI2_LDW_FCW_PCAN_OUT: id 0x18FE5BE8, from CGW, frame-length=8, can-addressing-mode=EXTENDED
          pdu FLI2_LDW_FCW_PCAN_OUT: length=8, transmission-mode-false-timing=event-controlled-timing=number-of-repetitions=0, transmission-mode-true-timing=event-controlled-timing=number-of-repetitions=0
        frame VDHR_Tachograph_DTG_CAN_CLOCK_PCAN_OUT: id 0x18FEC1EE, from CGW, frame-length=8, can-addressing-mode=EXTENDED
          pdu VDHR_Tachograph_DTG_CAN_CLOCK_PCAN_OUT: length=8, transmission-mode-false-timing=event-controlled-timing=number-of-repetitions=0, transmission-mode-true-timing=event-controlled-timing=number-of-repetitions=0
    Can_Network_SCAN
      can physical channel Can_Network_SCAN_Channel: comm-connectors=Conn_Can_Network_SCAN_CGW
        frame TSC1_E_ABS_EBS_SCAN_IN: id 0xC00000B, to CGW, frame-length=8, can-addressing-mode=EXTENDED, can-frame-rx-behavior=ANY
          pdu TSC1_E_ABS_EBS_SCAN_IN: length=8, transmission-mode-false-timing=event-controlled-timing=number-of-repetitions=0, transmission-mode-true-timing=event-controlled-timing=number-of-repetitions=0
        frame TSC1_DR_ABS_EBS_SCAN_IN: id 0xC00100B, to CGW, frame-length=8, can-addressing-mode=EXTENDED, can-frame-rx-behavior=ANY
          pdu TSC1_DR_ABS_EBS_SCAN_IN: length=8, transmission-mode-false-timing=event-controlled-timing=number-of-repetitions=0, transmission-mode-true-timing=event-controlled-timing=number-of-repetitions=0
        frame DM1_ABS_EBS_SCAN_IN: id 0x18FECA0B, to CGW, frame-length=22, can-addressing-mode=EXTENDED, can-frame-rx-behavior=ANY
          pdu DM1_ABS_EBS_SCAN_IN: length=22, transmission-mode-false-timing=event-controlled-timing=number-of-repetitions=0, transmission-mode-true-timing=event-controlled-timing=number-of-repetitions=0
        frame EBC5_ABS_EBS_SCAN_IN: id 0x18FDC40B, to CGW, frame-length=4, can-addressing-mode=EXTENDED, can-frame-rx-behavior=ANY
          pdu EBC5_ABS_EBS_SCAN_IN: length=4, transmission-mode-false-timing=event-controlled-timing=number-of-repetitions=0, transmission-mode-true-timing=event-controlled-timing=number-of-repetitions=0
            transmission-mode-conditions:
              {data-filter={data-filter-type=ALWAYS, max=250, min=0}, i-signal-in-i-pdu=OverallIntendedBrakeAcceleration_EBC5_ABS_EBS_SCAN}
              {data-filter={data-filter-type=ALWAYS, max=250, min=0}, i-signal-in-i-pdu=DriverBrakeDemand_EBC5_ABS_EBS_SCAN}
              {data-filter={data-filter-type=ALWAYS, max=15, min=0, offset=0}, i-signal-in-i-pdu=XBRBrakeHoldMode_EBC5_ABS_EBS_SCAN}
              {data-filter={data-filter-type=ALWAYS, max=3, min=0, offset=0}, i-signal-in-i-pdu=RailroadMode_EBC5_ABS_EBS_SCAN}
              {data-filter={data-filter-type=ALWAYS, max=0, min=0, offset=0}, i-signal-in-i-pdu=EmergencyBrakingActive_EBC5_ABS_EBS_SCAN}
              {data-filter={data-filter-type=ALWAYS, max=3, min=0, offset=0}, i-signal-in-i-pdu=BrakeTempWarning_EBC5_ABS_EBS_SCAN}
              {data-filter={data-filter-type=ALWAYS, max=250, min=0}, i-signal-in-i-pdu=XBRAccelerationLimit_EBC5_ABS_EBS_SCAN}
              {data-filter={data-filter-type=ALWAYS, max=15, min=0, offset=0}, i-signal-in-i-pdu=XBRActiveCtrlMode_EBC5_ABS_EBS_SCAN}
              {data-filter={data-filter-type=ALWAYS, max=3, min=0, offset=0}, i-signal-in-i-pdu=XBRSystemState_EBC5_ABS_EBS_SCAN}
              {data-filter={data-filter-type=ALWAYS, max=3, min=0, offset=0}, i-signal-in-i-pdu=FoundationBrakeUse_EBC5_ABS_EBS_SCAN}
              {data-filter={data-filter-type=ALWAYS, max=7, min=0, offset=0}, i-signal-in-i-pdu=HillHolderMode_EBC5_ABS_EBS_SCAN}
              {data-filter={data-filter-type=ALWAYS, max=7, min=0, offset=0}, i-signal-in-i-pdu=HaltBrakeMode_EBC5_ABS_EBS_SCAN}
              {data-filter={data-filter-type=ALWAYS, max=3, min=0, offset=0}, i-signal-in-i-pdu=PrkngBrakeActuatorFullyActivated_EBC5_ABS_EBS_SCAN}
            signal OverallIntendedBrakeAcceleration_EBC5_ABS_EBS_SCAN: start 48, 8 bit, little-endian, init-value=0, base-type=uint8, to CGW
            signal DriverBrakeDemand_EBC5_ABS_EBS_SCAN: start 40, 8 bit, little-endian, init-value=0, base-type=uint8, to CGW
            signal XBRBrakeHoldMode_EBC5_ABS_EBS_SCAN: start 32, 4 bit, little-endian, init-value=0, base-type=uint8, to CGW
            signal RailroadMode_EBC5_ABS_EBS_SCAN: start 28, 2 bit, little-endian, init-value=0, base-type=uint8, to CGW
            signal EmergencyBrakingActive_EBC5_ABS_EBS_SCAN: start 26, 2 bit, little-endian, init-value=0, base-type=uint8, to CGW
            signal BrakeTempWarning_EBC5_ABS_EBS_SCAN: start 0, 2 bit, little-endian, init-value=0, base-type=uint8, to CGW  # This parameter indicates if the temperature in the service brakes exceeds a certain value.This parameter indicates if the temperature in the service brakes exceeds a certain value. It can be used for a warningThis parameter indicates if the temperature in the service brakes exceeds a certain value."
            signal XBRAccelerationLimit_EBC5_ABS_EBS_SCAN: start 16, 8 bit, little-endian, init-value=125, base-type=uint8, to CGW  # The brake system may temporarily or generally limit the maximum brake performance available for external systems.The brake system may temporarily or generally limit the maximum brake performance available for external systems. AThe brake system may temporarily or generally limit the maximum brake performance available for external systems."
            signal XBRActiveCtrlMode_EBC5_ABS_EBS_SCAN: start 12, 4 bit, little-endian, init-value=0, base-type=uint8, to CGW  # This parameter indicates which XBR Control Mode is executed by the brake system.This parameter indicates which XBR Control Mode is executed by the brake system.This parameter indicates which XBR Control Mode is executed by the brake system."
            signal XBRSystemState_EBC5_ABS_EBS_SCAN: start 10, 2 bit, little-endian, init-value=0, base-type=uint8, to CGW  # This parameter indicates which external brake control is allowed.This parameter indicates which external brake control is allowed.This parameter indicates which external brake control is allowed."
            signal FoundationBrakeUse_EBC5_ABS_EBS_SCAN: start 8, 2 bit, little-endian, init-value=0, base-type=uint8, to CGW  # This parameter indicates if the brake system presently uses the foundation brakes.This parameter indicates if the brake system presently uses the foundation brakes.This parameter indicates if the brake system presently uses the foundation brakes."
            signal HillHolderMode_EBC5_ABS_EBS_SCAN: start 5, 3 bit, little-endian, init-value=0, base-type=uint8, to CGW  # Signal which indicates the current mode of the hill holder function.Signal which indicates the current mode of the hill holder function.Signal which indicates the current mode of the hill holder function."
            signal HaltBrakeMode_EBC5_ABS_EBS_SCAN: start 2, 3 bit, little-endian, init-value=0, base-type=uint8, to CGW  # Signal which indicates the current mode of the halt brake function.Signal which indicates the current mode of the halt brake function.Signal which indicates the current mode of the halt brake function."
            signal PrkngBrakeActuatorFullyActivated_EBC5_ABS_EBS_SCAN: start 24, 2 bit, little-endian, init-value=0, base-type=uint8, to CGW  # Signal which indicates when the parking brake actuator is fully activated."
        frame TSC1_DrvR_ACC_ACC_SCAN_IN: id 0xC00102A, to CGW, frame-length=8, can-addressing-mode=EXTENDED, can-frame-rx-behavior=ANY
          pdu TSC1_DrvR_ACC_ACC_SCAN_IN: length=8, transmission-mode-false-timing=event-controlled-timing=number-of-repetitions=0, transmission-mode-true-timing=event-controlled-timing=number-of-repetitions=0
        frame DM1_ACC_ACC_SCAN_IN: id 0x18FECA2A, to CGW, frame-length=22, can-addressing-mode=EXTENDED, can-frame-rx-behavior=ANY
          pdu DM1_ACC_ACC_SCAN_IN: length=22, transmission-mode-false-timing=event-controlled-timing=number-of-repetitions=0, transmission-mode-true-timing=event-controlled-timing=number-of-repetitions=0
        frame DM1_ECAS_SCAN_IN: id 0x18FECA2F, to CGW, frame-length=22, can-addressing-mode=EXTENDED, can-frame-rx-behavior=ANY
          pdu DM1_ECAS_SCAN_IN: length=22, transmission-mode-false-timing=event-controlled-timing=number-of-repetitions=0, transmission-mode-true-timing=event-controlled-timing=number-of-repetitions=0
        frame FLIC_LDW_FCW_SWRC_SCAN_IN: id 0x18A90031, to CGW, frame-length=8, can-addressing-mode=EXTENDED, can-frame-rx-behavior=ANY
          pdu FLIC_LDW_FCW_SWRC_SCAN_IN: length=8, transmission-mode-condition{data-filter={data-filter-type=ALWAYS, max=3, min=0, offset=0}, i-signal-in-i-pdu=LaneDepartureWarningEnableCmd_FLIC_LDW_FCW_SWRC_SCAN}, transmission-mode-false-timing=event-controlled-timing=number-of-repetitions=0, transmission-mode-true-timing=event-controlled-timing=number-of-repetitions=0
            signal LaneDepartureWarningEnableCmd_FLIC_LDW_FCW_SWRC_SCAN: start 0, 2 bit, little-endian, init-value=0, base-type=uint8, to CGW
        frame VW_ALCS_ECAS_SCAN_IN: id 0x18FEEA2F, to CGW, frame-length=8, can-addressing-mode=EXTENDED, can-frame-rx-behavior=ANY
          pdu VW_ALCS_ECAS_SCAN_IN: length=8, transmission-mode-false-timing=event-controlled-timing=number-of-repetitions=0, transmission-mode-true-timing=event-controlled-timing=number-of-repetitions=0
        frame ASC1_A_ECAS_ECAS_SCAN_IN: id 0xCFE5A2F, to CGW, frame-length=8, can-addressing-mode=EXTENDED, can-frame-rx-behavior=ANY
          pdu ASC1_A_ECAS_ECAS_SCAN_IN: length=8, transmission-mode-false-timing=event-controlled-timing=number-of-repetitions=0, transmission-mode-true-timing=event-controlled-timing=number-of-repetitions=0
        frame DM1_DSM_SCAN_IN: id 0x18FECA41, to CGW, frame-length=22, can-addressing-mode=EXTENDED, can-frame-rx-behavior=ANY
          pdu DM1_DSM_SCAN_IN: length=22, transmission-mode-false-timing=event-controlled-timing=number-of-repetitions=0, transmission-mode-true-timing=event-controlled-timing=number-of-repetitions=0
        frame SWRC2AVN_SWRC_SCAN_IN: id 0x18FF1C66, to CGW, frame-length=8, can-addressing-mode=EXTENDED, can-frame-rx-behavior=ANY
          pdu SWRC2AVN_SWRC_SCAN_IN: length=8, transmission-mode-false-timing=event-controlled-timing=number-of-repetitions=0, transmission-mode-true-timing=event-controlled-timing=number-of-repetitions=0
        frame DM1_PAS_SCAN_IN: id 0x18FECA7A, to CGW, frame-length=22, can-addressing-mode=EXTENDED, can-frame-rx-behavior=ANY
          pdu DM1_PAS_SCAN_IN: length=22, transmission-mode-false-timing=event-controlled-timing=number-of-repetitions=0, transmission-mode-true-timing=event-controlled-timing=number-of-repetitions=0
        frame DM01_AEBS_AEB_SCAN_IN: id 0x18FECAA0, to CGW, frame-length=22, can-addressing-mode=EXTENDED, can-frame-rx-behavior=ANY
          pdu DM01_AEBS_AEB_SCAN_IN: length=22, transmission-mode-false-timing=event-controlled-timing=number-of-repetitions=0, transmission-mode-true-timing=event-controlled-timing=number-of-repetitions=0
        frame DM1_LDW_FCW_SCAN_IN: id 0x18FECAE8, to CGW, frame-length=22, can-addressing-mode=EXTENDED, can-frame-rx-behavior=ANY
          pdu DM1_LDW_FCW_SCAN_IN: length=22, transmission-mode-false-timing=event-controlled-timing=number-of-repetitions=0, transmission-mode-true-timing=event-controlled-timing=number-of-repetitions=0
        frame TSC1_EXR_ABS_EBS_SCAN_IN: id 0xC00290B, to CGW, frame-length=8, can-addressing-mode=EXTENDED, can-frame-rx-behavior=ANY
          pdu TSC1_EXR_ABS_EBS_SCAN_IN: length=8, transmission-mode-false-timing=event-controlled-timing=number-of-repetitions=0, transmission-mode-true-timing=event-controlled-timing=number-of-repetitions=0
        frame EBC1_ABS_EBS_SCAN_IN: id 0x18F0010B, to CGW, frame-length=8, can-addressing-mode=EXTENDED, can-frame-rx-behavior=ANY
          pdu EBC1_ABS_EBS_SCAN_IN: length=8, transmission-mode-false-timing=event-controlled-timing=number-of-repetitions=0, transmission-mode-true-timing=event-controlled-timing=number-of-repetitions=0
        frame EBC2_ABS_EBS_SCAN_IN: id 0x18FEBF0B, to CGW, frame-length=8, can-addressing-mode=EXTENDED, can-frame-rx-behavior=ANY
          pdu EBC2_ABS_EBS_SCAN_IN: length=8, transmission-mode-false-timing=event-controlled-timing=number-of-repetitions=0, transmission-mode-true-timing=event-controlled-timing=number-of-repetitions=0
        frame TSC1_ER_ABS_EBS_SCAN_IN: id 0xC000F0B, to CGW, frame-length=8, can-addressing-mode=EXTENDED, can-frame-rx-behavior=ANY
          pdu TSC1_ER_ABS_EBS_SCAN_IN: length=8, transmission-mode-false-timing=event-controlled-timing=number-of-repetitions=0, transmission-mode-true-timing=event-controlled-timing=number-of-repetitions=0
        frame VDC1_ABS_EBS_SCAN_IN: id 0x18FE4F0B, to CGW, frame-length=8, can-addressing-mode=EXTENDED, can-frame-rx-behavior=ANY
          pdu VDC1_ABS_EBS_SCAN_IN: length=8, transmission-mode-false-timing=event-controlled-timing=number-of-repetitions=0, transmission-mode-true-timing=event-controlled-timing=number-of-repetitions=0
        frame ACC1_ACC_ACC_SCAN_IN: id 0x10FE6F2A, to CGW, frame-length=8, can-addressing-mode=EXTENDED, can-frame-rx-behavior=ANY
          pdu ACC1_ACC_ACC_SCAN_IN: length=8, transmission-mode-false-timing=event-controlled-timing=number-of-repetitions=0, transmission-mode-true-timing=event-controlled-timing=number-of-repetitions=0
        frame ACC2_SMD_SMD_SCAN_IN: id 0x18FE5131, to CGW, frame-length=8, can-addressing-mode=EXTENDED, can-frame-rx-behavior=ANY
          pdu ACC2_SMD_SMD_SCAN_IN: length=8, transmission-mode-false-timing=event-controlled-timing=number-of-repetitions=0, transmission-mode-true-timing=event-controlled-timing=number-of-repetitions=0
        frame ACC2_SWRC_SWRC_SCAN_IN: id 0x18FE5131, to CGW, frame-length=8, can-addressing-mode=EXTENDED, can-frame-rx-behavior=ANY
          pdu ACC2_SWRC_SWRC_SCAN_IN: length=8, transmission-mode-false-timing=event-controlled-timing=number-of-repetitions=0, transmission-mode-true-timing=event-controlled-timing=number-of-repetitions=0
        frame DSM1_DSM_SCAN_IN: id 0x18FF1741, to CGW, frame-length=8, can-addressing-mode=EXTENDED, can-frame-rx-behavior=ANY
          pdu DSM1_DSM_SCAN_IN: length=8, transmission-mode-false-timing=event-controlled-timing=number-of-repetitions=0, transmission-mode-true-timing=event-controlled-timing=number-of-repetitions=0
        frame SWRC2IC_SWRC_SCAN_IN: id 0x18FB1766, to CGW, frame-length=8, can-addressing-mode=EXTENDED, can-frame-rx-behavior=ANY
          pdu SWRC2IC_SWRC_SCAN_IN: length=8, transmission-mode-false-timing=event-controlled-timing=number-of-repetitions=0, transmission-mode-true-timing=event-controlled-timing=number-of-repetitions=0
        frame CWI1_PAS_SCAN_IN: id 0x18E0177A, to CGW, frame-length=8, can-addressing-mode=EXTENDED, can-frame-rx-behavior=ANY
          pdu CWI1_PAS_SCAN_IN: length=8, transmission-mode-false-timing=event-controlled-timing=number-of-repetitions=0, transmission-mode-true-timing=event-controlled-timing=number-of-repetitions=0
        frame CWI2_PAS_SCAN_IN: id 0x18E1177A, to CGW, frame-length=8, can-addressing-mode=EXTENDED, can-frame-rx-behavior=ANY
          pdu CWI2_PAS_SCAN_IN: length=8, transmission-mode-false-timing=event-controlled-timing=number-of-repetitions=0, transmission-mode-true-timing=event-controlled-timing=number-of-repetitions=0
        frame AEBS1_AEBS_AEB_SCAN_IN: id 0xCF02FA0, to CGW, frame-length=8, can-addressing-mode=EXTENDED, can-frame-rx-behavior=ANY
          pdu AEBS1_AEBS_AEB_SCAN_IN: length=8, transmission-mode-false-timing=event-controlled-timing=number-of-repetitions=0, transmission-mode-true-timing=event-controlled-timing=number-of-repetitions=0
        frame FLI2_LDW_FCW_SCAN_IN: id 0x18FE5BE8, to CGW, frame-length=8, can-addressing-mode=EXTENDED, can-frame-rx-behavior=ANY
          pdu FLI2_LDW_FCW_SCAN_IN: length=8, transmission-mode-false-timing=event-controlled-timing=number-of-repetitions=0, transmission-mode-true-timing=event-controlled-timing=number-of-repetitions=0
        frame ETC1_TCU_SCAN_OUT: id 0xCF00203, from CGW, frame-length=8, can-addressing-mode=EXTENDED
          pdu ETC1_TCU_SCAN_OUT: length=8, transmission-mode-false-timing=event-controlled-timing=number-of-repetitions=0, transmission-mode-true-timing=event-controlled-timing=number-of-repetitions=0
        frame ETC7_TCU_SCAN_OUT: id 0x18FE4A03, from CGW, frame-length=8, can-addressing-mode=EXTENDED
          pdu ETC7_TCU_SCAN_OUT: length=8, transmission-mode-false-timing=event-controlled-timing=number-of-repetitions=0, transmission-mode-true-timing=event-controlled-timing=number-of-repetitions=0
        frame ERC1_ER_ECU_SCAN_OUT: id 0x18F0000F, from CGW, frame-length=8, can-addressing-mode=EXTENDED
          pdu ERC1_ER_ECU_SCAN_OUT: length=8, transmission-mode-false-timing=event-controlled-timing=number-of-repetitions=0, transmission-mode-true-timing=event-controlled-timing=number-of-repetitions=0
        frame ERC1_DR_ITR_SCAN_OUT: id 0x18F00010, from CGW, frame-length=8, can-addressing-mode=EXTENDED
          pdu ERC1_DR_ITR_SCAN_OUT: length=8, transmission-mode-false-timing=event-controlled-timing=number-of-repetitions=0, transmission-mode-true-timing=event-controlled-timing=number-of-repetitions=0
        frame EPSO2_EHPS_SCAN_OUT: id 0x18FF0613, from CGW, frame-length=8, can-addressing-mode=EXTENDED
          pdu EPSO2_EHPS_SCAN_OUT: length=8, transmission-mode-false-timing=event-controlled-timing=number-of-repetitions=0, transmission-mode-true-timing=event-controlled-timing=number-of-repetitions=0
        frame RQST_I_IC_SCAN_OUT: id 0x18EA0017, from CGW, frame-length=8, can-addressing-mode=EXTENDED
          pdu RQST_I_IC_SCAN_OUT: length=8, transmission-mode-false-timing=event-controlled-timing=number-of-repetitions=0, transmission-mode-true-timing=event-controlled-timing=number-of-repetitions=0
        frame ETC7_BCM_CMD_SCAN_OUT: id 0x18FE4A21, from CGW, frame-length=8, can-addressing-mode=EXTENDED
          pdu ETC7_BCM_CMD_SCAN_OUT: length=8, transmission-mode-false-timing=event-controlled-timing=number-of-repetitions=0, transmission-mode-true-timing=event-controlled-timing=number-of-repetitions=0
        frame EEC1_ECU_SCAN_OUT: id 0xCF00400, from CGW, frame-length=8, can-addressing-mode=EXTENDED
          pdu EEC1_ECU_SCAN_OUT: length=8, transmission-mode-false-timing=event-controlled-timing=number-of-repetitions=0, transmission-mode-true-timing=event-controlled-timing=number-of-repetitions=0
        frame RQST_D_IC_SCAN_OUT: id 0x18EA0027, from CGW, frame-length=8, can-addressing-mode=EXTENDED
          pdu RQST_D_IC_SCAN_OUT: length=8, transmission-mode-false-timing=event-controlled-timing=number-of-repetitions=0, transmission-mode-true-timing=event-controlled-timing=number-of-repetitions=0
        frame Brakes_RTM_SCAN_OUT: id 0x18FEFA27, from CGW, frame-length=8, can-addressing-mode=EXTENDED
          pdu Brakes_RTM_SCAN_OUT: length=8, transmission-mode-false-timing=event-controlled-timing=number-of-repetitions=0, transmission-mode-true-timing=event-controlled-timing=number-of-repetitions=0
        frame AIR1_IC_SCAN_OUT: id 0x18FEAE30, from CGW, frame-length=8, can-addressing-mode=EXTENDED
          pdu AIR1_IC_SCAN_OUT: length=8, transmission-mode-false-timing=event-controlled-timing=number-of-repetitions=0, transmission-mode-true-timing=event-controlled-timing=number-of-repetitions=0
        frame CCVS3_ECU_SCAN_OUT: id 0x18FCDC00, from CGW, frame-length=1, can-addressing-mode=EXTENDED
          pdu CCVS3_ECU_SCAN_OUT: length=1, transmission-mode-false-timing=event-controlled-timing=number-of-repetitions=0, transmission-mode-true-timing=event-controlled-timing=number-of-repetitions=0
        frame TCO1_Tachograph_DTG_CAN_CLOCK_SCAN_OUT: id 0xCFE6CEE, from CGW, frame-length=8, can-addressing-mode=EXTENDED
          pdu TCO1_Tachograph_DTG_CAN_CLOCK_SCAN_OUT: length=8, transmission-mode-false-timing=event-controlled-timing=number-of-repetitions=0, transmission-mode-true-timing=event-controlled-timing=number-of-repetitions=0
        frame TD_DTG_CAN_CLOCK_SCAN_OUT: id 0x18FEE6EE, from CGW, frame-length=8, can-addressing-mode=EXTENDED
          pdu TD_DTG_CAN_CLOCK_SCAN_OUT: length=8, transmission-mode-false-timing=event-controlled-timing=number-of-repetitions=0, transmission-mode-true-timing=event-controlled-timing=number-of-repetitions=0
        frame TxCCVS_ECU_SCAN_OUT: id 0x18FEF100, from CGW, frame-length=8, can-addressing-mode=EXTENDED
          pdu TxCCVS_ECU_SCAN_OUT: length=8, transmission-mode-false-timing=event-controlled-timing=number-of-repetitions=0, transmission-mode-true-timing=event-controlled-timing=number-of-repetitions=0
        frame EEC3_ECU_SCAN_OUT: id 0x18FEDF00, from CGW, frame-length=8, can-addressing-mode=EXTENDED
          pdu EEC3_ECU_SCAN_OUT: length=8, transmission-mode-false-timing=event-controlled-timing=number-of-repetitions=0, transmission-mode-true-timing=event-controlled-timing=number-of-repetitions=0
        frame EC1_ECU_SCAN_OUT: id 0x18FEE300, from CGW, frame-length=39, can-addressing-mode=EXTENDED
          pdu EC1_ECU_SCAN_OUT: length=39, transmission-mode-false-timing=event-controlled-timing=number-of-repetitions=0, transmission-mode-true-timing=event-controlled-timing=number-of-repetitions=0
        frame EEC2_ECU_SCAN_OUT: id 0xCF00300, from CGW, frame-length=8, can-addressing-mode=EXTENDED
          pdu EEC2_ECU_SCAN_OUT: length=8, transmission-mode-false-timing=event-controlled-timing=number-of-repetitions=0, transmission-mode-true-timing=event-controlled-timing=number-of-repetitions=0
        frame ETC2_TCU_SCAN_OUT: id 0x18F00503, from CGW, frame-length=8, can-addressing-mode=EXTENDED
          pdu ETC2_TCU_SCAN_OUT: length=8, transmission-mode-false-timing=event-controlled-timing=number-of-repetitions=0, transmission-mode-true-timing=event-controlled-timing=number-of-repetitions=0
        frame SAS1_EHPS_SCAN_OUT: id 0x18F01D13, from CGW, frame-length=8, can-addressing-mode=EXTENDED
          pdu SAS1_EHPS_SCAN_OUT: length=8, transmission-mode-false-timing=event-controlled-timing=number-of-repetitions=0, transmission-mode-true-timing=event-controlled-timing=number-of-repetitions=0
        frame SAS2_EHPS_SCAN_OUT: id 0x18F01D14, from CGW, frame-length=8, can-addressing-mode=EXTENDED
          pdu SAS2_EHPS_SCAN_OUT: length=8, transmission-mode-false-timing=event-controlled-timing=number-of-repetitions=0, transmission-mode-true-timing=event-controlled-timing=number-of-repetitions=0
        frame EPSO1_EHPS_SCAN_OUT: id 0x18FF0513, from CGW, frame-length=8, can-addressing-mode=EXTENDED
          pdu EPSO1_EHPS_SCAN_OUT: length=8, transmission-mode-false-timing=event-controlled-timing=number-of-repetitions=0, transmission-mode-true-timing=event-controlled-timing=number-of-repetitions=0
        frame IC2SP1_IC_SCAN_OUT: id 0x18FF3117, from CGW, frame-length=8, can-addressing-mode=EXTENDED
          pdu IC2SP1_IC_SCAN_OUT: length=8, transmission-mode-false-timing=event-controlled-timing=number-of-repetitions=0, transmission-mode-true-timing=event-controlled-timing=number-of-repetitions=0
        frame IC2SP2_IC_SCAN_OUT: id 0x18FB3117, from CGW, frame-length=8, can-addressing-mode=EXTENDED
          pdu IC2SP2_IC_SCAN_OUT: length=8, transmission-mode-false-timing=event-controlled-timing=number-of-repetitions=0, transmission-mode-true-timing=event-controlled-timing=number-of-repetitions=0
        frame RQST_EBC4_IC_SCAN_OUT: id 0x18EA0B17, from CGW, frame-length=8, can-addressing-mode=EXTENDED
          pdu RQST_EBC4_IC_SCAN_OUT: length=8, transmission-mode-false-timing=event-controlled-timing=number-of-repetitions=0, transmission-mode-true-timing=event-controlled-timing=number-of-repetitions=0
        frame OEL_IC_SCAN_OUT: id 0xCFDCC27, from CGW, frame-length=8, can-addressing-mode=EXTENDED
          pdu OEL_IC_SCAN_OUT: length=8, transmission-mode-false-timing=event-controlled-timing=number-of-repetitions=0, transmission-mode-true-timing=event-controlled-timing=number-of-repetitions=0
        frame CCVS1_SA2_RTM_SCAN_OUT: id 0x18FEF127, from CGW, frame-length=8, can-addressing-mode=EXTENDED
          pdu CCVS1_SA2_RTM_SCAN_OUT: length=8, transmission-mode-false-timing=event-controlled-timing=number-of-repetitions=0, transmission-mode-true-timing=event-controlled-timing=number-of-repetitions=0
        frame ASC2_A_BCM_CMD_SCAN_OUT: id 0xCD22F27, from CGW, frame-length=8, can-addressing-mode=EXTENDED
          pdu ASC2_A_BCM_CMD_SCAN_OUT: length=8, transmission-mode-false-timing=event-controlled-timing=number-of-repetitions=0, transmission-mode-true-timing=event-controlled-timing=number-of-repetitions=0
        frame EBC1_CCM_SCAN_OUT: id 0x18F00131, from CGW, frame-length=8, can-addressing-mode=EXTENDED
          pdu EBC1_CCM_SCAN_OUT: length=8, transmission-mode-false-timing=event-controlled-timing=number-of-repetitions=0, transmission-mode-true-timing=event-controlled-timing=number-of-repetitions=0
        frame CACI5_HVAC_SCAN_OUT: id 0x18FC1C19, from CGW, frame-length=8, can-addressing-mode=EXTENDED
          pdu CACI5_HVAC_SCAN_OUT: length=8, transmission-mode-false-timing=event-controlled-timing=number-of-repetitions=0, transmission-mode-true-timing=event-controlled-timing=number-of-repetitions=0
        frame CACI6_HVAC_SCAN_OUT: id 0x18FB1C19, from CGW, frame-length=8, can-addressing-mode=EXTENDED
          pdu CACI6_HVAC_SCAN_OUT: length=8, transmission-mode-false-timing=event-controlled-timing=number-of-repetitions=0, transmission-mode-true-timing=event-controlled-timing=number-of-repetitions=0
        frame VDHR_Tachograph_DTG_CAN_CLOCK_SCAN_OUT: id 0x18FEC1EE, from CGW, frame-length=8, can-addressing-mode=EXTENDED
          pdu VDHR_Tachograph_DTG_CAN_CLOCK_SCAN_OUT: length=8, transmission-mode-false-timing=event-controlled-timing=number-of-repetitions=0, transmission-mode-true-timing=event-controlled-timing=number-of-repetitions=0
